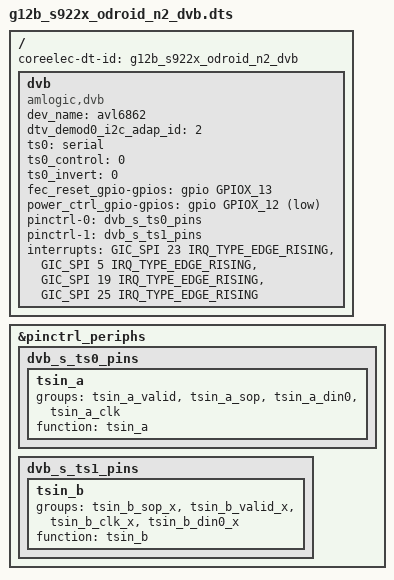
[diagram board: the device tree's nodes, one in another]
#include "g12b_s922x_odroid_n2.dts"

/{
	coreelec-dt-id = "g12b_s922x_odroid_n2_dvb";

	dvb {
		compatible = "amlogic,dvb";
		dev_name = "avl6862";
		status = "okay";
		dtv_demod0_i2c_adap_id = <2>;
		ts0 = "serial";
		ts0_control = <0>;
		ts0_invert = <0>;
		fec_reset_gpio-gpios = <&gpio GPIOX_13 GPIO_ACTIVE_HIGH>;
		power_ctrl_gpio-gpios = <&gpio GPIOX_12 GPIO_ACTIVE_LOW>;
		pinctrl-names = "s_ts0", "s_ts1";
		pinctrl-0 = <&dvb_s_ts0_pins>;
		pinctrl-1 = <&dvb_s_ts1_pins>;
		interrupts = <GIC_SPI 23 IRQ_TYPE_EDGE_RISING>,
			     <GIC_SPI  5 IRQ_TYPE_EDGE_RISING>,
			     <GIC_SPI 19 IRQ_TYPE_EDGE_RISING>,
			     <GIC_SPI 25 IRQ_TYPE_EDGE_RISING>;
		interrupt-names = "demux0", "demux1", "asyncfifo0", "asyncfifo1";
	};
};

&pinctrl_periphs {
	dvb_s_ts0_pins: dvb_s_ts0_pins {
		tsin_a {
			groups ="tsin_a_valid",
				"tsin_a_sop",
				"tsin_a_din0",
				"tsin_a_clk";
			function = "tsin_a";
		};
	};

	dvb_s_ts1_pins: dvb_s_ts1_pins {
		tsin_b {
			groups = "tsin_b_sop_x",
			"tsin_b_valid_x",
			"tsin_b_clk_x",
			"tsin_b_din0_x";
			function = "tsin_b";
		};
	};
};
